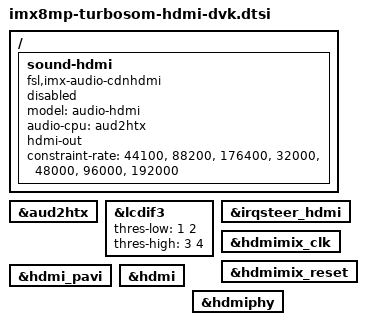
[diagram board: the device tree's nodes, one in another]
// SPDX-License-Identifier: (GPL-2.0+ OR MIT)
/*
 * Copyright 2021 Laird Connectivity
 */

/ {
	sound-hdmi {
		compatible = "fsl,imx-audio-cdnhdmi";
		model = "audio-hdmi";
		audio-cpu = <&aud2htx>;
		hdmi-out;
		constraint-rate = <44100>,
				<88200>,
				<176400>,
				<32000>,
				<48000>,
				<96000>,
				<192000>;
		status = "disabled";
	};
};

&aud2htx {
	status = "okay";
};

&lcdif3 {
	status = "okay";

	thres-low  = <1 2>;             /* (FIFO * 1 / 2) */
	thres-high = <3 4>;             /* (FIFO * 3 / 4) */
};

&irqsteer_hdmi {
	status = "okay";
};

&hdmimix_clk {
	status = "okay";
};

&hdmimix_reset {
	status = "okay";
};

&hdmi_pavi {
	status = "okay";
};

&hdmi {
	status = "okay";
};

&hdmiphy {
	status = "okay";
};
